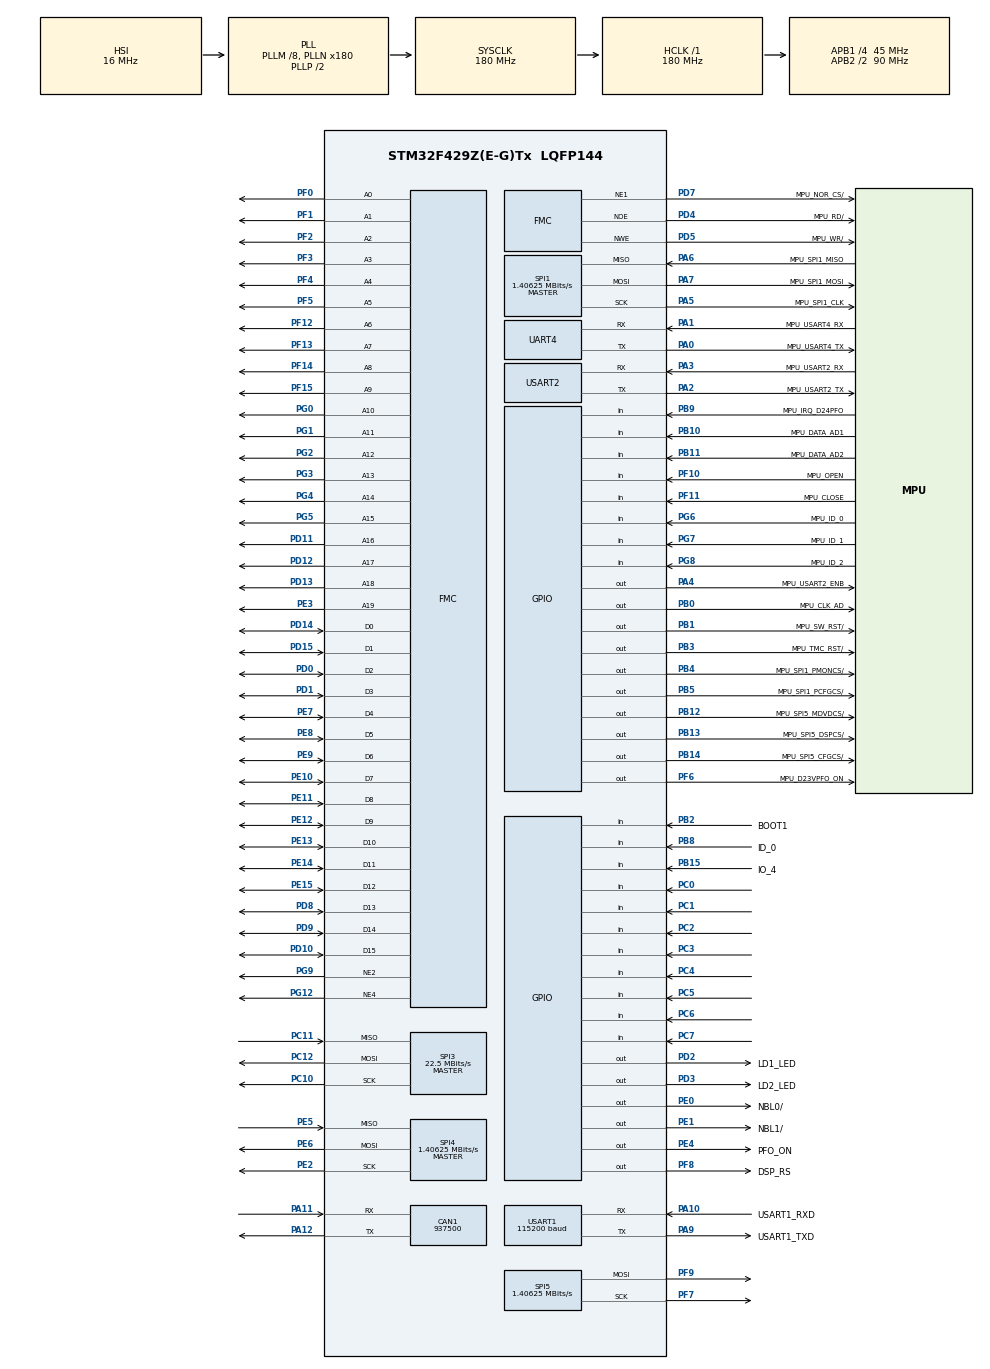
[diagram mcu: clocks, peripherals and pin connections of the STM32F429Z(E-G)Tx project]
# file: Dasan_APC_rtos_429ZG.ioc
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CAN1.CalculateBaudRate=937500
CAN1.CalculateTimeBit=1066
CAN1.CalculateTimeQuantum=355.55555555555554
Dma.Request0=USART1_RX
Dma.USART1_RX.0.Direction=DMA_PERIPH_TO_MEMORY
Dma.USART1_RX.0.FIFOMode=DMA_FIFOMODE_DISABLE
Dma.USART1_RX.0.Instance=DMA2_Stream2
Dma.USART1_RX.0.MemDataAlignment=DMA_MDATAALIGN_BYTE
Dma.USART1_RX.0.MemInc=DMA_MINC_ENABLE
Dma.USART1_RX.0.Mode=DMA_CIRCULAR
Dma.USART1_RX.0.PeriphDataAlignment=DMA_PDATAALIGN_BYTE
Dma.USART1_RX.0.PeriphInc=DMA_PINC_DISABLE
Dma.USART1_RX.0.Priority=DMA_PRIORITY_MEDIUM
FMC.AccessMode1=FMC_ACCESS_MODE_C
FMC.AddressSetupTime1=10
FMC.BusTurnAroundDuration1=15
FMC.DataSetupTime1=10
FMC.ExtendedAccessMode1=FMC_ACCESS_MODE_C
FMC.ExtendedAddressSetupTime1=10
FMC.ExtendedDataSetupTime1=100
FMC.ExtendedMode1=FMC_EXTENDED_MODE_ENABLE
FMC.ExtendedMode2=FMC_EXTENDED_MODE_ENABLE
FMC.ExtendedMode4=FMC_EXTENDED_MODE_ENABLE
FMC.WriteOperation1=FMC_WRITE_OPERATION_DISABLE
FMC.WriteOperation2=FMC_WRITE_OPERATION_ENABLE
FMC.WriteOperation4=FMC_WRITE_OPERATION_ENABLE
FREERTOS.HEAP_NUMBER=4
FREERTOS.INCLUDE_eTaskGetState=1
FREERTOS.INCLUDE_pcTaskGetTaskName=0
FREERTOS.INCLUDE_uxTaskGetStackHighWaterMark=1
FREERTOS.INCLUDE_uxTaskGetStackHighWaterMark2=0
FREERTOS.INCLUDE_uxTaskPriorityGet=1
FREERTOS.INCLUDE_vTaskCleanUpResources=0
FREERTOS.INCLUDE_vTaskDelay=1
FREERTOS.INCLUDE_vTaskDelayUntil=1
FREERTOS.INCLUDE_vTaskDelete=1
FREERTOS.INCLUDE_vTaskPrioritySet=1
FREERTOS.INCLUDE_vTaskSuspend=1
FREERTOS.INCLUDE_xEventGroupSetBitFromISR=0
FREERTOS.INCLUDE_xQueueGetMutexHolder=1
FREERTOS.INCLUDE_xSemaphoreGetMutexHolder=0
FREERTOS.INCLUDE_xTaskAbortDelay=0
FREERTOS.INCLUDE_xTaskGetCurrentTaskHandle=1
FREERTOS.INCLUDE_xTaskGetHandle=0
FREERTOS.INCLUDE_xTaskGetSchedulerState=1
FREERTOS.INCLUDE_xTaskResumeFromISR=1
FREERTOS.INCLUDE_xTimerPendFunctionCall=1
FREERTOS.Queues01=jobQueue,16,uint32_t,0,Dynamic,NULL,NULL
FREERTOS.Tasks01=defaultTask,24,256,StartDefaultTask,Default,NULL,Dynamic,NULL,NULL;asyncTask,16,128,StartAsyncTask,Default,NULL,Dynamic,NULL,NULL;pidTask,40,128,StartPidTask,Default,NULL,Dynamic,NULL,NULL;pollTask,8,128,StartPollTask,Default,NULL,Dynamic,NULL,NULL
FREERTOS.configCHECK_FOR_STACK_OVERFLOW=0
FREERTOS.configENABLE_BACKWARD_COMPATIBILITY=1
FREERTOS.configENABLE_FPU=0
FREERTOS.configGENERATE_RUN_TIME_STATS=0
FREERTOS.configIDLE_SHOULD_YIELD=1
FREERTOS.configLIBRARY_LOWEST_INTERRUPT_PRIORITY=15
FREERTOS.configLIBRARY_MAX_SYSCALL_INTERRUPT_PRIORITY=5
FREERTOS.configMAX_CO_ROUTINE_PRIORITIES=2
FREERTOS.configMAX_TASK_NAME_LEN=16
FREERTOS.configMINIMAL_STACK_SIZE=128
FREERTOS.configQUEUE_REGISTRY_SIZE=8
FREERTOS.configRECORD_STACK_HIGH_ADDRESS=0
FREERTOS.configTICK_RATE_HZ=1000
FREERTOS.configTIMER_QUEUE_LENGTH=10
FREERTOS.configTIMER_TASK_PRIORITY=2
FREERTOS.configTIMER_TASK_STACK_DEPTH=256
FREERTOS.configTOTAL_HEAP_SIZE=15360
FREERTOS.configUSE_APPLICATION_TASK_TAG=0
FREERTOS.configUSE_COUNTING_SEMAPHORES=1
FREERTOS.configUSE_CO_ROUTINES=0
FREERTOS.configUSE_DAEMON_TASK_STARTUP_HOOK=0
FREERTOS.configUSE_IDLE_HOOK=0
FREERTOS.configUSE_MALLOC_FAILED_HOOK=0
FREERTOS.configUSE_MUTEXES=1
FREERTOS.configUSE_NEWLIB_REENTRANT=1
FREERTOS.configUSE_OS2_EVENTFLAGS_FROM_ISR=1
FREERTOS.configUSE_OS2_MUTEX=1
FREERTOS.configUSE_OS2_THREAD_ENUMERATE=1
FREERTOS.configUSE_OS2_THREAD_FLAGS=1
FREERTOS.configUSE_OS2_THREAD_SUSPEND_RESUME=1
FREERTOS.configUSE_OS2_TIMER=1
FREERTOS.configUSE_POSIX_ERRNO=0
FREERTOS.configUSE_PREEMPTION=1
FREERTOS.configUSE_RECURSIVE_MUTEXES=1
FREERTOS.configUSE_STATS_FORMATTING_FUNCTIONS=0
FREERTOS.configUSE_TASK_NOTIFICATIONS=1
FREERTOS.configUSE_TICKLESS_IDLE=0
FREERTOS.configUSE_TICK_HOOK=0
FREERTOS.configUSE_TRACE_FACILITY=1
FREERTOS.copyHeapFile=1
Mcu.Family=STM32F4
Mcu.Name=STM32F429Z(E-G)Tx
Mcu.Package=LQFP144
NVIC.DMA2_Stream2_IRQn=true\:5\:0\:false\:false\:true\:false\:true\:true\:true
NVIC.PriorityGroup=NVIC_PRIORITYGROUP_4
NVIC.TIM6_DAC_IRQn=true\:5\:0\:true\:false\:true\:true\:true\:true\:true
NVIC.TIM7_IRQn=true\:15\:0\:false\:false\:true\:false\:true\:true\:true
NVIC.TimeBase=TIM7_IRQn
NVIC.TimeBaseIP=TIM7
NVIC.UART4_IRQn=true\:5\:0\:false\:false\:true\:true\:true\:true\:true
NVIC.USART2_IRQn=true\:5\:0\:false\:false\:true\:true\:true\:true\:true
PA0/WKUP.GPIO_Label=MPU_USART4_TX
PA0/WKUP.Mode=Asynchronous
PA0/WKUP.Signal=UART4_TX
PA1.GPIO_Label=MPU_USART4_RX
PA1.Mode=Asynchronous
PA1.Signal=UART4_RX
PA10.GPIO_Label=USART1_RXD
PA10.Mode=Asynchronous
PA10.Signal=USART1_RX
PA11.Mode=CAN_Activate
PA11.Signal=CAN1_RX
PA12.Mode=CAN_Activate
PA12.Signal=CAN1_TX
PA13.GPIO_Label=DB_SWDIO
PA13.Mode=Serial_Wire
PA13.Signal=SYS_JTMS-SWDIO
PA14.GPIO_Label=DB_SWCLK
PA14.Mode=Serial_Wire
PA14.Signal=SYS_JTCK-SWCLK
PA2.GPIO_Label=MPU_USART2_TX
PA2.Mode=Asynchronous
PA2.Signal=USART2_TX
PA3.GPIO_Label=MPU_USART2_RX
PA3.Mode=Asynchronous
PA3.Signal=USART2_RX
PA4.GPIO_Label=MPU_USART2_ENB
PA4.Signal=GPIO_Output
PA5.GPIO_Label=MPU_SPI1_CLK
PA5.Mode=Full_Duplex_Master
PA5.Signal=SPI1_SCK
PA6.GPIO_Label=MPU_SPI1_MISO
PA6.Mode=Full_Duplex_Master
PA6.Signal=SPI1_MISO
PA7.GPIO_Label=MPU_SPI1_MOSI
PA7.Mode=Full_Duplex_Master
PA7.Signal=SPI1_MOSI
PA9.GPIO_Label=USART1_TXD
PA9.Mode=Asynchronous
PA9.Signal=USART1_TX
PB0.GPIO_Label=MPU_CLK_AD
PB0.GPIO_Speed=GPIO_SPEED_FREQ_LOW
PB0.Signal=GPIO_Output
PB1.GPIO_Label=MPU_SW_RST/
PB1.PinState=GPIO_PIN_RESET
PB1.Signal=GPIO_Output
PB10.GPIO_Label=MPU_DATA_AD1
PB10.Signal=GPIO_Input
PB11.GPIO_Label=MPU_DATA_AD2
PB11.Signal=GPIO_Input
PB12.GPIO_Label=MPU_SPI5_MDVDCS/
PB12.GPIO_Speed=GPIO_SPEED_FREQ_VERY_HIGH
PB12.PinState=GPIO_PIN_SET
PB12.Signal=GPIO_Output
PB13.GPIO_Label=MPU_SPI5_DSPCS/
PB13.GPIO_Speed=GPIO_SPEED_FREQ_VERY_HIGH
PB13.PinState=GPIO_PIN_SET
PB13.Signal=GPIO_Output
PB14.GPIO_Label=MPU_SPI5_CFGCS/
PB14.GPIO_Speed=GPIO_SPEED_FREQ_VERY_HIGH
PB14.PinState=GPIO_PIN_SET
PB14.Signal=GPIO_Output
PB15.GPIO_Label=IO_4
PB15.Signal=GPIO_Input
PB2/BOOT1.GPIO_Label=BOOT1
PB2/BOOT1.Signal=GPIO_Input
PB3.GPIO_Label=MPU_TMC_RST/
PB3.PinState=GPIO_PIN_SET
PB3.Signal=GPIO_Output
PB4.GPIO_Label=MPU_SPI1_PMONCS/
PB4.Signal=GPIO_Output
PB5.GPIO_Label=MPU_SPI1_PCFGCS/
PB5.Signal=GPIO_Output
PB8.GPIO_Label=ID_0
PB8.Signal=GPIO_Input
PB9.GPIO_Label=MPU_IRQ_D24PFO
PB9.Signal=GPIO_Input
PC0.Signal=GPIO_Input
PC1.Signal=GPIO_Input
PC10.Mode=Full_Duplex_Master
PC10.Signal=SPI3_SCK
PC11.Mode=Full_Duplex_Master
PC11.Signal=SPI3_MISO
PC12.Mode=Full_Duplex_Master
PC12.Signal=SPI3_MOSI
PC2.Signal=GPIO_Input
PC3.Signal=GPIO_Input
PC4.Signal=GPIO_Input
PC5.Signal=GPIO_Input
PC6.Signal=GPIO_Input
PC7.Signal=GPIO_Input
PD0.Signal=FMC_D2_DA2
PD1.Signal=FMC_D3_DA3
PD10.Signal=FMC_D15_DA15
PD11.Signal=FMC_A16_CLE
PD12.Signal=FMC_A17_ALE
PD13.Signal=FMC_A18
PD14.Signal=FMC_D0_DA0
PD15.Signal=FMC_D1_DA1
PD2.GPIO_Label=LD1_LED
PD2.Signal=GPIO_Output
PD3.GPIO_Label=LD2_LED
PD3.Signal=GPIO_Output
PD4.GPIO_Label=MPU_RD/
PD4.GPIO_PuPd=GPIO_NOPULL
PD4.Signal=FMC_NOE
PD5.GPIO_Label=MPU_WR/
PD5.GPIO_PuPd=GPIO_NOPULL
PD5.Signal=FMC_NWE
PD7.GPIO_Label=MPU_NOR_CS/
PD7.Mode=NorPsramChipSelect1_1
PD7.Signal=FMC_NE1
PD8.Signal=FMC_D13_DA13
PD9.Signal=FMC_D14_DA14
PE0.GPIO_Label=NBL0/
PE0.PinState=GPIO_PIN_RESET
PE0.Signal=GPIO_Output
PE1.GPIO_Label=NBL1/
PE1.PinState=GPIO_PIN_RESET
PE1.Signal=GPIO_Output
PE10.Signal=FMC_D7_DA7
PE11.Signal=FMC_D8_DA8
PE12.Signal=FMC_D9_DA9
PE13.Signal=FMC_D10_DA10
PE14.Signal=FMC_D11_DA11
PE15.Signal=FMC_D12_DA12
PE2.Mode=Full_Duplex_Master
PE2.Signal=SPI4_SCK
PE3.Signal=FMC_A19
PE4.GPIO_Label=PFO_ON
PE4.Signal=GPIO_Output
PE5.Mode=Full_Duplex_Master
PE5.Signal=SPI4_MISO
PE6.Mode=Full_Duplex_Master
PE6.Signal=SPI4_MOSI
PE7.Signal=FMC_D4_DA4
PE8.Signal=FMC_D5_DA5
PE9.Signal=FMC_D6_DA6
PF0.Signal=FMC_A0
PF1.Signal=FMC_A1
PF10.GPIO_Label=MPU_OPEN
PF10.Signal=GPIO_Input
PF11.GPIO_Label=MPU_CLOSE
PF11.Signal=GPIO_Input
PF12.Signal=FMC_A6
PF13.Signal=FMC_A7
PF14.Signal=FMC_A8
PF15.Signal=FMC_A9
PF2.Signal=FMC_A2
PF3.Signal=FMC_A3
PF4.Signal=FMC_A4
PF5.Signal=FMC_A5
PF6.GPIO_Label=MPU_D23VPFO_ON
PF6.Signal=GPIO_Output
PF7.Mode=TX_Only_Simplex_Unidirect_Master
PF7.Signal=SPI5_SCK
PF8.GPIO_Label=DSP_RS
PF8.PinState=GPIO_PIN_SET
PF8.Signal=GPIO_Output
PF9.Mode=TX_Only_Simplex_Unidirect_Master
PF9.Signal=SPI5_MOSI
PG0.Signal=FMC_A10
PG1.Signal=FMC_A11
PG12.Mode=NorPsramChipSelect4_4
PG12.Signal=FMC_NE4
PG2.Signal=FMC_A12
PG3.Signal=FMC_A13
PG4.Signal=FMC_A14_BA0
PG5.Signal=FMC_A15_BA1
PG6.GPIO_Label=MPU_ID_0
PG6.Signal=GPIO_Input
PG7.GPIO_Label=MPU_ID_1
PG7.Signal=GPIO_Input
PG8.GPIO_Label=MPU_ID_2
PG8.Signal=GPIO_Input
PG9.Mode=NorPsramChipSelect2_2
PG9.Signal=FMC_NE2
PH0/OSC_IN.GPIO_Label=XTAL1
PH0/OSC_IN.Mode=HSE-External-Oscillator
PH0/OSC_IN.Signal=RCC_OSC_IN
PH1/OSC_OUT.GPIO_Label=XTAL2
PH1/OSC_OUT.Mode=HSE-External-Oscillator
PH1/OSC_OUT.Signal=RCC_OSC_OUT
ProjectManager.HeapSize=0x200
ProjectManager.StackSize=0x400
ProjectManager.TargetToolchain=STM32CubeIDE
RCC.48MHZClocksFreq_Value=90000000
RCC.AHBFreq_Value=180000000
RCC.APB1CLKDivider=RCC_HCLK_DIV4
RCC.APB1Freq_Value=45000000
RCC.APB1TimFreq_Value=90000000
RCC.APB2CLKDivider=RCC_HCLK_DIV2
RCC.APB2Freq_Value=90000000
RCC.APB2TimFreq_Value=180000000
RCC.CortexFreq_Value=180000000
RCC.FLatency=FLASH_LATENCY_5
RCC.HCLKFreq_Value=180000000
RCC.HSE_VALUE=16000000
RCC.HSI_VALUE=16000000
RCC.LSE_VALUE=32768
RCC.PLLM=8
RCC.PLLN=180
RCC.PWR_Regulator_Voltage_Scale=PWR_REGULATOR_VOLTAGE_SCALE1
RCC.SYSCLKFreq_VALUE=180000000
RCC.SYSCLKSource=RCC_SYSCLKSOURCE_PLLCLK
RCC.VCOOutputFreq_Value=360000000
SH.FMC_A0.0=FMC_A0,19b-a1
SH.FMC_A0.1=FMC_A0,16b-a2
SH.FMC_A0.2=FMC_A0,20b-a4
SH.FMC_A1.0=FMC_A1,19b-a1
SH.FMC_A1.1=FMC_A1,16b-a2
SH.FMC_A1.2=FMC_A1,20b-a4
SH.FMC_A10.0=FMC_A10,19b-a1
SH.FMC_A10.1=FMC_A10,16b-a2
SH.FMC_A10.2=FMC_A10,20b-a4
SH.FMC_A11.0=FMC_A11,19b-a1
SH.FMC_A11.1=FMC_A11,16b-a2
SH.FMC_A11.2=FMC_A11,20b-a4
SH.FMC_A12.0=FMC_A12,19b-a1
SH.FMC_A12.1=FMC_A12,16b-a2
SH.FMC_A12.2=FMC_A12,20b-a4
SH.FMC_A13.0=FMC_A13,19b-a1
SH.FMC_A13.1=FMC_A13,16b-a2
SH.FMC_A13.2=FMC_A13,20b-a4
SH.FMC_A14_BA0.0=FMC_A14,19b-a1
SH.FMC_A14_BA0.1=FMC_A14,16b-a2
SH.FMC_A14_BA0.2=FMC_A14,20b-a4
SH.FMC_A15_BA1.0=FMC_A15,19b-a1
SH.FMC_A15_BA1.1=FMC_A15,16b-a2
SH.FMC_A15_BA1.2=FMC_A15,20b-a4
SH.FMC_A16_CLE.0=FMC_A16,19b-a1
SH.FMC_A16_CLE.1=FMC_A16,20b-a4
SH.FMC_A17_ALE.0=FMC_A17,19b-a1
SH.FMC_A17_ALE.1=FMC_A17,20b-a4
SH.FMC_A18.0=FMC_A18,19b-a1
SH.FMC_A18.1=FMC_A18,20b-a4
SH.FMC_A19.0=FMC_A19,20b-a4
SH.FMC_A2.0=FMC_A2,19b-a1
SH.FMC_A2.1=FMC_A2,16b-a2
SH.FMC_A2.2=FMC_A2,20b-a4
SH.FMC_A3.0=FMC_A3,19b-a1
SH.FMC_A3.1=FMC_A3,16b-a2
SH.FMC_A3.2=FMC_A3,20b-a4
SH.FMC_A4.0=FMC_A4,19b-a1
SH.FMC_A4.1=FMC_A4,16b-a2
SH.FMC_A4.2=FMC_A4,20b-a4
SH.FMC_A5.0=FMC_A5,19b-a1
SH.FMC_A5.1=FMC_A5,16b-a2
SH.FMC_A5.2=FMC_A5,20b-a4
SH.FMC_A6.0=FMC_A6,19b-a1
SH.FMC_A6.1=FMC_A6,16b-a2
SH.FMC_A6.2=FMC_A6,20b-a4
SH.FMC_A7.0=FMC_A7,19b-a1
SH.FMC_A7.1=FMC_A7,16b-a2
SH.FMC_A7.2=FMC_A7,20b-a4
SH.FMC_A8.0=FMC_A8,19b-a1
SH.FMC_A8.1=FMC_A8,16b-a2
SH.FMC_A8.2=FMC_A8,20b-a4
SH.FMC_A9.0=FMC_A9,19b-a1
SH.FMC_A9.1=FMC_A9,16b-a2
SH.FMC_A9.2=FMC_A9,20b-a4
SH.FMC_D0_DA0.0=FMC_D0,16b-d1
SH.FMC_D0_DA0.1=FMC_D0,16b-d2
SH.FMC_D0_DA0.2=FMC_D0,8b-d4
SH.FMC_D10_DA10.0=FMC_D10,16b-d1
SH.FMC_D10_DA10.1=FMC_D10,16b-d2
SH.FMC_D11_DA11.0=FMC_D11,16b-d1
SH.FMC_D11_DA11.1=FMC_D11,16b-d2
SH.FMC_D12_DA12.0=FMC_D12,16b-d1
SH.FMC_D12_DA12.1=FMC_D12,16b-d2
SH.FMC_D13_DA13.0=FMC_D13,16b-d1
SH.FMC_D13_DA13.1=FMC_D13,16b-d2
SH.FMC_D14_DA14.0=FMC_D14,16b-d1
SH.FMC_D14_DA14.1=FMC_D14,16b-d2
SH.FMC_D15_DA15.0=FMC_D15,16b-d1
SH.FMC_D15_DA15.1=FMC_D15,16b-d2
SH.FMC_D1_DA1.0=FMC_D1,16b-d1
SH.FMC_D1_DA1.1=FMC_D1,16b-d2
SH.FMC_D1_DA1.2=FMC_D1,8b-d4
SH.FMC_D2_DA2.0=FMC_D2,16b-d1
SH.FMC_D2_DA2.1=FMC_D2,16b-d2
SH.FMC_D2_DA2.2=FMC_D2,8b-d4
SH.FMC_D3_DA3.0=FMC_D3,16b-d1
SH.FMC_D3_DA3.1=FMC_D3,16b-d2
SH.FMC_D3_DA3.2=FMC_D3,8b-d4
SH.FMC_D4_DA4.0=FMC_D4,16b-d1
SH.FMC_D4_DA4.1=FMC_D4,16b-d2
SH.FMC_D4_DA4.2=FMC_D4,8b-d4
SH.FMC_D5_DA5.0=FMC_D5,16b-d1
SH.FMC_D5_DA5.1=FMC_D5,16b-d2
SH.FMC_D5_DA5.2=FMC_D5,8b-d4
SH.FMC_D6_DA6.0=FMC_D6,16b-d1
SH.FMC_D6_DA6.1=FMC_D6,16b-d2
SH.FMC_D6_DA6.2=FMC_D6,8b-d4
SH.FMC_D7_DA7.0=FMC_D7,16b-d1
SH.FMC_D7_DA7.1=FMC_D7,16b-d2
SH.FMC_D7_DA7.2=FMC_D7,8b-d4
SH.FMC_D8_DA8.0=FMC_D8,16b-d1
SH.FMC_D8_DA8.1=FMC_D8,16b-d2
SH.FMC_D9_DA9.0=FMC_D9,16b-d1
SH.FMC_D9_DA9.1=FMC_D9,16b-d2
SH.FMC_NOE.0=FMC_NOE,NorFlash1
SH.FMC_NOE.1=FMC_NOE,Sram2
SH.FMC_NOE.2=FMC_NOE,Sram4
SH.FMC_NWE.0=FMC_NWE,NorFlash1
SH.FMC_NWE.1=FMC_NWE,Sram2
SH.FMC_NWE.2=FMC_NWE,Sram4
SPI1.BaudRatePrescaler=SPI_BAUDRATEPRESCALER_64
SPI1.CLKPhase=SPI_PHASE_1EDGE
SPI1.CLKPolarity=SPI_POLARITY_LOW
SPI1.CRCCalculation=SPI_CRCCALCULATION_DISABLE
SPI1.CalculateBaudRate=1.40625 MBits/s
SPI1.DataSize=SPI_DATASIZE_8BIT
SPI1.Direction=SPI_DIRECTION_2LINES
SPI1.FirstBit=SPI_FIRSTBIT_MSB
SPI1.Mode=SPI_MODE_MASTER
SPI1.NSS=SPI_NSS_SOFT
SPI1.TIMode=SPI_TIMODE_DISABLE
SPI1.VirtualType=VM_MASTER
SPI3.CalculateBaudRate=22.5 MBits/s
SPI3.Direction=SPI_DIRECTION_2LINES
SPI3.Mode=SPI_MODE_MASTER
SPI3.VirtualType=VM_MASTER
SPI4.BaudRatePrescaler=SPI_BAUDRATEPRESCALER_64
SPI4.CalculateBaudRate=1.40625 MBits/s
SPI4.Direction=SPI_DIRECTION_2LINES
SPI4.Mode=SPI_MODE_MASTER
SPI4.VirtualType=VM_MASTER
SPI5.BaudRatePrescaler=SPI_BAUDRATEPRESCALER_64
SPI5.CalculateBaudRate=1.40625 MBits/s
SPI5.Direction=SPI_DIRECTION_2LINES
SPI5.Mode=SPI_MODE_MASTER
SPI5.VirtualType=VM_MASTER
TIM3.AutoReloadPreload=TIM_AUTORELOAD_PRELOAD_DISABLE
TIM3.ClockDivision=TIM_CLOCKDIVISION_DIV1
TIM3.CounterMode=TIM_COUNTERMODE_UP
TIM3.Period=65535
TIM3.Prescaler=100-1
TIM3.TIM_MasterOutputTrigger=TIM_TRGO_RESET
TIM3.TIM_MasterSlaveMode=TIM_MASTERSLAVEMODE_DISABLE
TIM6.AutoReloadPreload=TIM_AUTORELOAD_PRELOAD_DISABLE
TIM6.CounterMode=TIM_COUNTERMODE_UP
TIM6.Period=1000-1
TIM6.Prescaler=100-1
TIM6.TIM_MasterOutputTrigger=TIM_TRGO_RESET
UART4.VirtualMode=Asynchronous
USART1.BaudRate=115200
USART1.Mode=MODE_TX_RX
USART1.OverSampling=UART_OVERSAMPLING_16
USART1.Parity=PARITY_NONE
USART1.StopBits=STOPBITS_1
USART1.VirtualMode=VM_ASYNC
USART1.WordLength=WORDLENGTH_8B
USART2.VirtualMode=VM_ASYNC
VP_FREERTOS_VS_CMSIS_V2.Mode=CMSIS_V2
VP_SYS_VS_tim7.Mode=TIM7
VP_TIM3_VS_ClockSourceINT.Mode=Internal
VP_TIM6_VS_ClockSourceINT.Mode=Enable_Timer
board=custom

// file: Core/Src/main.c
/* USER CODE BEGIN Header */
/**
  ******************************************************************************
  * @file           : main.c
  * @brief          : Main program body
  * version 		: 20251114_DNet_add
  ******************************************************************************
  * @attention
  *
  * Copyright (c) 2024 STMicroelectronics.
  * All rights reserved.
  *
  * This software is licensed under terms that can be found in the LICENSE file
  * in the root directory of this software component.
  * If no LICENSE file comes with this software, it is provided AS-IS.
  *
  ******************************************************************************
  */
/* USER CODE END Header */
#include "main.h"
#include "cmsis_os.h"
#include "can.h"
#include "dma.h"
#include "spi.h"
#include "tim.h"
#include "usart.h"
#include "gpio.h"
#include "fmc.h"

/* USER CODE BEGIN Includes */
#include "APC_Main.h"
/* USER CODE END Includes */

void SystemClock_Config(void);
void MX_FREERTOS_Init(void);

int main(void)
{

  /* MCU Configuration--------------------------------------------------------*/

  /* Reset of all peripherals, Initializes the Flash interface and the Systick. */
  HAL_Init();

  /* Configure the system clock */
  SystemClock_Config();

  /* Initialize all configured peripherals */
  MX_GPIO_Init();
  MX_DMA_Init();
  MX_SPI1_Init();
  MX_USART1_UART_Init();
  MX_TIM6_Init();
  MX_TIM3_Init();
  MX_FMC_Init();
  MX_USART2_UART_Init();
  MX_SPI3_Init();
  MX_SPI5_Init();
  MX_UART4_Init();
  MX_CAN1_Init();
  MX_SPI4_Init();

  /* Init scheduler */
  osKernelInitialize();

  /* Call init function for freertos objects (in cmsis_os2.c) */
  MX_FREERTOS_Init();

  /* Start scheduler */
  osKernelStart();

  /* We should never get here as control is now taken by the scheduler */

  /* Infinite loop */
  while (1)
  {

  }
}

void SystemClock_Config(void)
{
  RCC_OscInitTypeDef RCC_OscInitStruct = {0};
  RCC_ClkInitTypeDef RCC_ClkInitStruct = {0};

  /** Configure the main internal regulator output voltage
  */
  __HAL_RCC_PWR_CLK_ENABLE();
  __HAL_PWR_VOLTAGESCALING_CONFIG(PWR_REGULATOR_VOLTAGE_SCALE1);

  /** Initializes the RCC Oscillators according to the specified parameters
  * in the RCC_OscInitTypeDef structure.
  */
  RCC_OscInitStruct.OscillatorType = RCC_OSCILLATORTYPE_HSI;
  RCC_OscInitStruct.HSIState = RCC_HSI_ON;
  RCC_OscInitStruct.HSICalibrationValue = RCC_HSICALIBRATION_DEFAULT;
  RCC_OscInitStruct.PLL.PLLState = RCC_PLL_ON;
  RCC_OscInitStruct.PLL.PLLSource = RCC_PLLSOURCE_HSI;
  RCC_OscInitStruct.PLL.PLLM = 8;
  RCC_OscInitStruct.PLL.PLLN = 180;
  RCC_OscInitStruct.PLL.PLLP = RCC_PLLP_DIV2;
  RCC_OscInitStruct.PLL.PLLQ = 4;
  if (HAL_RCC_OscConfig(&RCC_OscInitStruct) != HAL_OK)
  {
    Error_Handler();
  }

  /** Activate the Over-Drive mode
  */
  if (HAL_PWREx_EnableOverDrive() != HAL_OK)
  {
    Error_Handler();
  }

  /** Initializes the CPU, AHB and APB buses clocks
  */
  RCC_ClkInitStruct.ClockType = RCC_CLOCKTYPE_HCLK|RCC_CLOCKTYPE_SYSCLK
                              |RCC_CLOCKTYPE_PCLK1|RCC_CLOCKTYPE_PCLK2;
  RCC_ClkInitStruct.SYSCLKSource = RCC_SYSCLKSOURCE_PLLCLK;
  RCC_ClkInitStruct.AHBCLKDivider = RCC_SYSCLK_DIV1;
  RCC_ClkInitStruct.APB1CLKDivider = RCC_HCLK_DIV4;
  RCC_ClkInitStruct.APB2CLKDivider = RCC_HCLK_DIV2;

  if (HAL_RCC_ClockConfig(&RCC_ClkInitStruct, FLASH_LATENCY_5) != HAL_OK)
  {
    Error_Handler();
  }
}

void HAL_TIM_PeriodElapsedCallback(TIM_HandleTypeDef *htim)
{
  if (htim->Instance == TIM7) {
    HAL_IncTick();
  }
}

void Error_Handler(void)
{
  __disable_irq();
  while (1)
  {
  }
}

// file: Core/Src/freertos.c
/* USER CODE BEGIN Header */
/**
  ******************************************************************************
  * File Name          : freertos.c
  * Description        : Code for freertos applications
  ******************************************************************************
  * @attention
  *
  * Copyright (c) 2024 STMicroelectronics.
  * All rights reserved.
  *
  * This software is licensed under terms that can be found in the LICENSE file
  * in the root directory of this software component.
  * If no LICENSE file comes with this software, it is provided AS-IS.
  *
  ******************************************************************************
  */
/* USER CODE END Header */

#include "FreeRTOS.h"
#include "task.h"
#include "main.h"
#include "cmsis_os.h"

/* USER CODE BEGIN Includes */
#include "APC_Main.h"
#include "APC_AsyncHandler.h"
#include "APC_PidHandler.h"
#include "APC_Scheduler.h"
#include "APC_Synch.h"
#include "APC_ControlMode.h"
#include "APC_CompAir.h"
#include "APC_Power.h"

/* DeviceNet Integration - Added 2025-01-13 */
#include "AppDNS_DeviceNetTask.h"
/* USER CODE END Includes */

/* USER CODE BEGIN PD */
int stopPidRun_ = 0; //louis
/* USER CODE END PD */

/* Definitions for defaultTask */
osThreadId_t defaultTaskHandle;
const osThreadAttr_t defaultTask_attributes = {
  .name = "defaultTask",
  .stack_size = 256 * 4,
  .priority = (osPriority_t) osPriorityNormal,
};
/* Definitions for asyncTask */
osThreadId_t asyncTaskHandle;
const osThreadAttr_t asyncTask_attributes = {
  .name = "asyncTask",
  .stack_size = 128 * 4,
  .priority = (osPriority_t) osPriorityBelowNormal,
};
/* Definitions for pidTask */
osThreadId_t pidTaskHandle;
const osThreadAttr_t pidTask_attributes = {
  .name = "pidTask",
  .stack_size = 128 * 4,
  .priority = (osPriority_t) osPriorityHigh,
};
/* Definitions for pollTask */
osThreadId_t pollTaskHandle;
const osThreadAttr_t pollTask_attributes = {
  .name = "pollTask",
  .stack_size = 128 * 4,
  .priority = (osPriority_t) osPriorityAboveNormal,
};
/* Definitions for CheckInputTask */
osThreadId_t CheckInputTaskHandle;
const osThreadAttr_t CheckInputTask_attributes = {
        .name = "CheckInputTask",
        .stack_size = 128 * 4,
        .priority = (osPriority_t) osPriorityAboveNormal,
};
/* Definitions for jobQueue */
osMessageQueueId_t jobQueueHandle;
const osMessageQueueAttr_t jobQueue_attributes = {
  .name = "jobQueue"
};

void StartDefaultTask(void *argument);
void StartAsyncTask(void *argument);
void StartPidTask(void *argument);
void StartPollTask(void *argument);
void StartCheckInputTask(void *argument);

void MX_FREERTOS_Init(void); /* (MISRA C 2004 rule 8.1) */

void MX_FREERTOS_Init(void) {

  /* Create the queue(s) */
  /* creation of jobQueue */
  jobQueueHandle = osMessageQueueNew (16, sizeof(uint32_t), &jobQueue_attributes);

  /* USER CODE BEGIN RTOS_QUEUES */
  /* add queues, ... */
  //registerMQ(&jobQueueHandle);
  /* USER CODE END RTOS_QUEUES */

  /* Create the thread(s) */
  /* creation of defaultTask */
  defaultTaskHandle = osThreadNew(StartDefaultTask, NULL, &defaultTask_attributes);

  /* creation of asyncTask */
  asyncTaskHandle = osThreadNew(StartAsyncTask, NULL, &asyncTask_attributes);

  /* creation of pidTask */
  pidTaskHandle = osThreadNew(StartPidTask, NULL, &pidTask_attributes);

  /* creation of pollTask */
  pollTaskHandle = osThreadNew(StartPollTask, NULL, &pollTask_attributes);

  /* creation of CheckInputTask */
  //CheckInputTaskHandle = osThreadNew(StartCheckInputTask, NULL, &CheckInputTask_attributes);

  /* USER CODE BEGIN RTOS_THREADS */
  /* add threads, ... */

  /* DeviceNet Task - Added 2025-01-13
   * NOTE: Currently in STUB mode (ENABLE_DEVICENET=0 in DeviceNet_Config.h)
   * Enable full mode when cifXToolkit and DeviceNet SDK files are ready
   */
  AppDNS_DeviceNetTask_Create();

  /* USER CODE END RTOS_THREADS */

}

/* USER CODE BEGIN Header_StartDefaultTask */
#define ADDR_CS_IF1_     (1 << 17)
uint16_t readc = 0;
/**
  * @brief  Function implementing the defaultTask thread.
  * @param  argument: Not used
  * @retval None
  */
/* USER CODE END Header_StartDefaultTask */
void StartDefaultTask(void *argument)
{
  /* USER CODE BEGIN StartDefaultTask */
  initMain();

  uint32_t counter = 0;
  /* Infinite loop */
  for(;;)
  {
    osDelay(2);

#ifdef __REV_MTECH__
    // Check Thread Running
    HAL_GPIO_TogglePin(GPIOD, LD1_LED_Pin);
    //
#endif

    readc = readSRAM4(ADDR_CS_IF1_);
    printLocalRS232(APC_PORT_LOCAL, "[LOCAL INPUT] %02x\r\n", readc);
    // Test Relay
#if 1
    //writeRELAY_OPEN(APC_HIGH);
    //osDelay(1000);
    //writeRELAY_OPEN(APC_LOW);
    //osDelay(1000);

    writeRELAY_CLOSE(APC_HIGH);
    osDelay(1000);
    writeRELAY_CLOSE(APC_LOW);
    osDelay(1000);
#endif

    // Test DAC7612
#if 1
    writeAOUT_POSITION(0);
    writeAOUT_PRESSURE(30000);
    osDelay(500);
    //writeAOUT_POSITION(1000);
    writeAOUT_PRESSURE(20000);
    osDelay(500);
    //osDelay(1000);
    //writeAOUT_POSITION(2000);
    writeAOUT_PRESSURE(10000);
    osDelay(500);
    //osDelay(1000);
    writeAOUT_POSITION(100000);
    writeAOUT_PRESSURE(0);
    osDelay(500);
    //osDelay(1000);
#endif

    // Test MAX1116
#if 1
    osDelay(500);
    // in CONNECTOR
    refreshPower();

    // in MASTER
    transfer_VDRUCK_Spi();
#endif

#ifdef __REV_MTECH__
    uint8_t eeprom = 0;
    if(true == getE2promData(100, eeprom))	// forced true ???
    {
      printLocalRS232(APC_PORT_LOCAL, "[LOCAL DBG] %02x\r\n", eeprom);
    }

    eeprom = 0x55;
    if(true == setE2promData(100, eeprom))	// forced true ???
    {
      printLocalRS232(APC_PORT_LOCAL, "[LOCAL DBG] %02x\r\n", eeprom);
    }

    eeprom = 0;
    if(true == getE2promData(100, eeprom))	// forced true ???
    {
      printLocalRS232(APC_PORT_LOCAL, "[LOCAL DBG] %02x\r\n", eeprom);
    }

    //writeRemoteRS232Data()
    writeRemoteRS232Data((uint8_t *) "ABCDEFGH", strlen("ABCDEFGH"));
#endif

    procMain(counter);

    if (getInitStatus() == true) {
        scheduleSensor(counter);
        scheduleValve(counter);
        scheduleDisplay(counter);
        counter++;
    }
  }
  /* USER CODE END StartDefaultTask */
}

void StartAsyncTask(void *argument)
{
  /* USER CODE BEGIN StartAsyncTask */
  uint32_t counter = 0;
  /* Infinite loop */
  for(;;)
  {
    osDelay(5);
    procAsyncHandler(counter);
    counter++;
  }
  /* USER CODE END StartAsyncTask */
}

void StartPidTask(void *argument)
{
  /* USER CODE BEGIN StartPidTask */
  static uint32_t counter = 0; //louis
  static bool initJobExecuted = false;//l_0701_16
  extern double Ioutput_sum;
  extern double Prev_Error;
  /* Infinite loop */
  for(;;)
  {
#if 1
    osDelay(5);
#else
    if(getControlMode() != ControlMode_PRESSURE){
        setPidRunState(false);
       Ioutput_sum =0.0;
       Prev_Error = 0.0;
    }
    osDelay(5);

		if (stopPidRun_ == 1)  {
			setPidRunState(false);
			if (!initJobExecuted) {
				initJob();
				initJobExecuted = true; // Set the flag to true after executing initJob()
			}
		}

		if(getPidRunState() && (getControlMode() != ControlMode_PRESSURE)){
			setPidRunState(false);
			Ioutput_sum =0.0;
			Prev_Error = 0.0;
		}
		if (getSynchStatus() == true) {
			if(getPidRunState()){
				procPid();
				//            osDelay(30);//l,0708
				osDelay(5);//l,0708
				//            osDelay(1);//l,0708
				counter++;
			}
		}
#endif
  }
  /* USER CODE END StartPidTask */
}

void StartPollTask(void *argument)
{
  /* USER CODE BEGIN StartPollTask */
  uint32_t counter = 0;
  /* Infinite loop */
  for(;;)
  {
#if 1
  	osDelay(3);         // osDelay(1);
#else
  	osDelay(3);         // osDelay(1);

    if (getInitStatus() == true) {
        scheduleInterrupt(counter);
        //scheduleSensor(counter);
        //scheduleValve(counter);
        //scheduleDisplay(counter);
        schedulePower(counter);
        scheduleAir(counter);
        scheduleRemotePort(counter);
        counter++;
    }
#endif
  }
  /* USER CODE END StartPollTask */
}

void StartCheckInputTask(void *argument)
{
    /* USER CODE BEGIN StartCheckInputTask */
    uint32_t counter = 0;
    /* Infinite loop */
    while(true){
        if(getInitStatus() == true){
            scheduleInterrupt(counter);
            _cur_volt = getMax1116Value();
            _comp_air_val = getCompAir(APC_PORT_INTERNAL);      // Pendulum Isolation Type에서만 호출하도록.
            CheckRemote();
        }
        counter++;
        osDelay(10);        // 10ms delay
    }
}
